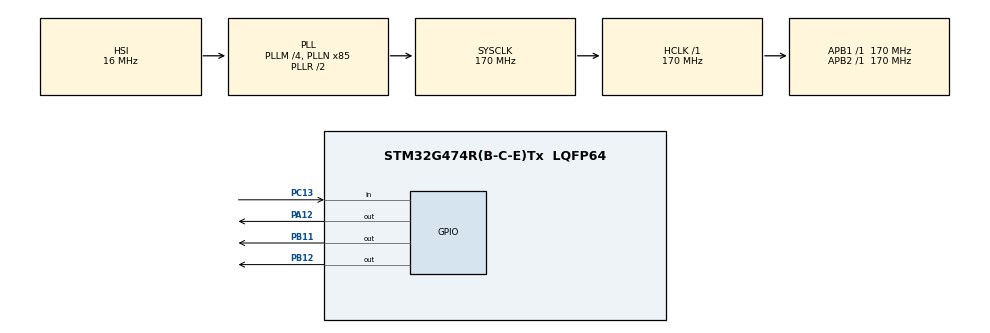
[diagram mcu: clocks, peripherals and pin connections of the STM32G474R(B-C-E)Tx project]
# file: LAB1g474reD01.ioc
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Mcu.Family=STM32G4
Mcu.Name=STM32G474R(B-C-E)Tx
Mcu.Package=LQFP64
NVIC.PriorityGroup=NVIC_PRIORITYGROUP_4
PA12.Signal=GPIO_Output
PA13.GPIO_Label=T_SWDIO
PA13.Signal=SYS_JTMS-SWDIO
PA14.GPIO_Label=T_SWCLK
PA14.Signal=SYS_JTCK-SWCLK
PA2.GPIO_Label=LPUART1_TX [STLINKV3E_VCP_RX]
PA2.Signal=LPUART1_TX
PA3.GPIO_Label=LPUART1_RX [STLINKV3E_VCP_TX]
PA3.Signal=LPUART1_RX
PB11.Signal=GPIO_Output
PB12.Signal=GPIO_Output
PB3.GPIO_Label=T_SWO
PB3.Signal=SYS_JTDO-SWO
PC13.Signal=GPIO_Input
PC14-OSC32_IN.GPIO_Label=RCC_OSC32_IN
PC14-OSC32_IN.Signal=RCC_OSC32_IN
PC15-OSC32_OUT.GPIO_Label=RCC_OSC32_OUT
PC15-OSC32_OUT.Signal=RCC_OSC32_OUT
PF0-OSC_IN.GPIO_Label=RCC_OSC_IN
PF0-OSC_IN.Signal=RCC_OSC_IN
PF1-OSC_OUT.GPIO_Label=RCC_OSC_OUT
PF1-OSC_OUT.Signal=RCC_OSC_OUT
ProjectManager.HeapSize=0x200
ProjectManager.StackSize=0x400
ProjectManager.TargetToolchain=STM32CubeIDE
RCC.ADC12Freq_Value=170000000
RCC.ADC345Freq_Value=170000000
RCC.AHBFreq_Value=170000000
RCC.APB1Freq_Value=170000000
RCC.APB1TimFreq_Value=170000000
RCC.APB2Freq_Value=170000000
RCC.APB2TimFreq_Value=170000000
RCC.CortexFreq_Value=170000000
RCC.EXTERNAL_CLOCK_VALUE=12288000
RCC.HCLKFreq_Value=170000000
RCC.HSE_VALUE=24000000
RCC.HSI48_VALUE=48000000
RCC.HSI_VALUE=16000000
RCC.LSE_VALUE=32768
RCC.PLLM=RCC_PLLM_DIV4
RCC.PLLN=85
RCC.RTCClockSelection=RCC_RTCCLKSOURCE_LSE
RCC.SYSCLKFreq_VALUE=170000000
RCC.SYSCLKSource=RCC_SYSCLKSOURCE_PLLCLK
RCC.USBFreq_Value=170000000
RCC.VCOOutputFreq_Value=340000000
VP_SYS_VS_DBSignals.Mode=DisableDeadBatterySignals
board=NUCLEO-G474RE

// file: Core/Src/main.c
/* USER CODE BEGIN Header */
/**
  ******************************************************************************
  * @file           : main.c
  * @brief          : Main program body
  ******************************************************************************
  * @attention
  *
  * Copyright (c) 2026 STMicroelectronics.
  * All rights reserved.
  *
  * This software is licensed under terms that can be found in the LICENSE file
  * in the root directory of this software component.
  * If no LICENSE file comes with this software, it is provided AS-IS.
  *
  ******************************************************************************
  */
/* USER CODE END Header */
#include "main.h"

void SystemClock_Config(void);
static void MX_GPIO_Init(void);

int main(void)
{
	int led_state = 0;        // 紀錄目前 LED 狀態
	int button_prev = 1;      // 初始狀態：未按 (PC13 = 1)

  /* MCU Configuration--------------------------------------------------------*/

  /* Reset of all peripherals, Initializes the Flash interface and the Systick. */
  HAL_Init();

  /* Configure the system clock */
  SystemClock_Config();

  /* Initialize all configured peripherals */
  MX_GPIO_Init();
  /* USER CODE BEGIN 2 */
	  // 初始 LED 全滅
	  HAL_GPIO_WritePin(GPIOA, GPIO_PIN_12, GPIO_PIN_RESET);
	  HAL_GPIO_WritePin(GPIOB, GPIO_PIN_11, GPIO_PIN_RESET);
	  HAL_GPIO_WritePin(GPIOB, GPIO_PIN_12, GPIO_PIN_RESET);
  /* USER CODE END 2 */

  /* Infinite loop */
  while (1)
  {
	  int button_now = HAL_GPIO_ReadPin(GPIOC, GPIO_PIN_13); // 讀取 USER BUTTON

	    // 偵測按鈕由未按(1) → 按下(0)
	    if (button_now == GPIO_PIN_RESET && button_prev == GPIO_PIN_SET)
	    {
	      led_state++;
	      if (led_state > 3) led_state = 0;

	      // 更新 LED 狀態
	      switch (led_state)
	      {
	        case 0: // 全滅
	          HAL_GPIO_WritePin(GPIOA, GPIO_PIN_12, GPIO_PIN_RESET);
	          HAL_GPIO_WritePin(GPIOB, GPIO_PIN_11, GPIO_PIN_RESET);
	          HAL_GPIO_WritePin(GPIOB, GPIO_PIN_12, GPIO_PIN_RESET);
	          break;

	        case 1: // 紅
	          HAL_GPIO_WritePin(GPIOA, GPIO_PIN_12, GPIO_PIN_SET);
	          HAL_GPIO_WritePin(GPIOB, GPIO_PIN_11, GPIO_PIN_RESET);
	          HAL_GPIO_WritePin(GPIOB, GPIO_PIN_12, GPIO_PIN_RESET);
	          break;

	        case 2: // 紅+黃
	          HAL_GPIO_WritePin(GPIOA, GPIO_PIN_12, GPIO_PIN_SET);
	          HAL_GPIO_WritePin(GPIOB, GPIO_PIN_11, GPIO_PIN_SET);
	          HAL_GPIO_WritePin(GPIOB, GPIO_PIN_12, GPIO_PIN_RESET);
	          break;

	        case 3: // 紅+黃+綠
	          HAL_GPIO_WritePin(GPIOA, GPIO_PIN_12, GPIO_PIN_SET);
	          HAL_GPIO_WritePin(GPIOB, GPIO_PIN_11, GPIO_PIN_SET);
	          HAL_GPIO_WritePin(GPIOB, GPIO_PIN_12, GPIO_PIN_SET);
	          break;
	      }
	    }

	    button_prev = button_now; // 更新前一次狀態
	    HAL_Delay(50);            // 消抖延遲
  }
}

void SystemClock_Config(void)
{
  RCC_OscInitTypeDef RCC_OscInitStruct = {0};
  RCC_ClkInitTypeDef RCC_ClkInitStruct = {0};

  /** Configure the main internal regulator output voltage
  */
  HAL_PWREx_ControlVoltageScaling(PWR_REGULATOR_VOLTAGE_SCALE1_BOOST);

  /** Initializes the RCC Oscillators according to the specified parameters
  * in the RCC_OscInitTypeDef structure.
  */
  RCC_OscInitStruct.OscillatorType = RCC_OSCILLATORTYPE_HSI;
  RCC_OscInitStruct.HSIState = RCC_HSI_ON;
  RCC_OscInitStruct.HSICalibrationValue = RCC_HSICALIBRATION_DEFAULT;
  RCC_OscInitStruct.PLL.PLLState = RCC_PLL_ON;
  RCC_OscInitStruct.PLL.PLLSource = RCC_PLLSOURCE_HSI;
  RCC_OscInitStruct.PLL.PLLM = RCC_PLLM_DIV4;
  RCC_OscInitStruct.PLL.PLLN = 85;
  RCC_OscInitStruct.PLL.PLLP = RCC_PLLP_DIV2;
  RCC_OscInitStruct.PLL.PLLQ = RCC_PLLQ_DIV2;
  RCC_OscInitStruct.PLL.PLLR = RCC_PLLR_DIV2;
  if (HAL_RCC_OscConfig(&RCC_OscInitStruct) != HAL_OK)
  {
    Error_Handler();
  }

  /** Initializes the CPU, AHB and APB buses clocks
  */
  RCC_ClkInitStruct.ClockType = RCC_CLOCKTYPE_HCLK|RCC_CLOCKTYPE_SYSCLK
                              |RCC_CLOCKTYPE_PCLK1|RCC_CLOCKTYPE_PCLK2;
  RCC_ClkInitStruct.SYSCLKSource = RCC_SYSCLKSOURCE_PLLCLK;
  RCC_ClkInitStruct.AHBCLKDivider = RCC_SYSCLK_DIV1;
  RCC_ClkInitStruct.APB1CLKDivider = RCC_HCLK_DIV1;
  RCC_ClkInitStruct.APB2CLKDivider = RCC_HCLK_DIV1;

  if (HAL_RCC_ClockConfig(&RCC_ClkInitStruct, FLASH_LATENCY_4) != HAL_OK)
  {
    Error_Handler();
  }
}

static void MX_GPIO_Init(void)
{
  GPIO_InitTypeDef GPIO_InitStruct = {0};

  /* GPIO Ports Clock Enable */
  __HAL_RCC_GPIOC_CLK_ENABLE();
  __HAL_RCC_GPIOF_CLK_ENABLE();
  __HAL_RCC_GPIOA_CLK_ENABLE();
  __HAL_RCC_GPIOB_CLK_ENABLE();

  /*Configure GPIO pin Output Level */
  HAL_GPIO_WritePin(GPIOB, GPIO_PIN_11|GPIO_PIN_12, GPIO_PIN_RESET);

  /*Configure GPIO pin Output Level */
  HAL_GPIO_WritePin(GPIOA, GPIO_PIN_12, GPIO_PIN_RESET);

  /*Configure GPIO pin : PC13 */
  GPIO_InitStruct.Pin = GPIO_PIN_13;
  GPIO_InitStruct.Mode = GPIO_MODE_INPUT;
  GPIO_InitStruct.Pull = GPIO_NOPULL;
  HAL_GPIO_Init(GPIOC, &GPIO_InitStruct);

  /*Configure GPIO pins : LPUART1_TX_Pin LPUART1_RX_Pin */
  GPIO_InitStruct.Pin = LPUART1_TX_Pin|LPUART1_RX_Pin;
  GPIO_InitStruct.Mode = GPIO_MODE_AF_PP;
  GPIO_InitStruct.Pull = GPIO_NOPULL;
  GPIO_InitStruct.Speed = GPIO_SPEED_FREQ_LOW;
  GPIO_InitStruct.Alternate = GPIO_AF12_LPUART1;
  HAL_GPIO_Init(GPIOA, &GPIO_InitStruct);

  /*Configure GPIO pins : PB11 PB12 */
  GPIO_InitStruct.Pin = GPIO_PIN_11|GPIO_PIN_12;
  GPIO_InitStruct.Mode = GPIO_MODE_OUTPUT_PP;
  GPIO_InitStruct.Pull = GPIO_NOPULL;
  GPIO_InitStruct.Speed = GPIO_SPEED_FREQ_LOW;
  HAL_GPIO_Init(GPIOB, &GPIO_InitStruct);

  /*Configure GPIO pin : PA12 */
  GPIO_InitStruct.Pin = GPIO_PIN_12;
  GPIO_InitStruct.Mode = GPIO_MODE_OUTPUT_PP;
  GPIO_InitStruct.Pull = GPIO_NOPULL;
  GPIO_InitStruct.Speed = GPIO_SPEED_FREQ_LOW;
  HAL_GPIO_Init(GPIOA, &GPIO_InitStruct);

}

void Error_Handler(void)
{
  __disable_irq();
  while (1)
  {
  }
}
